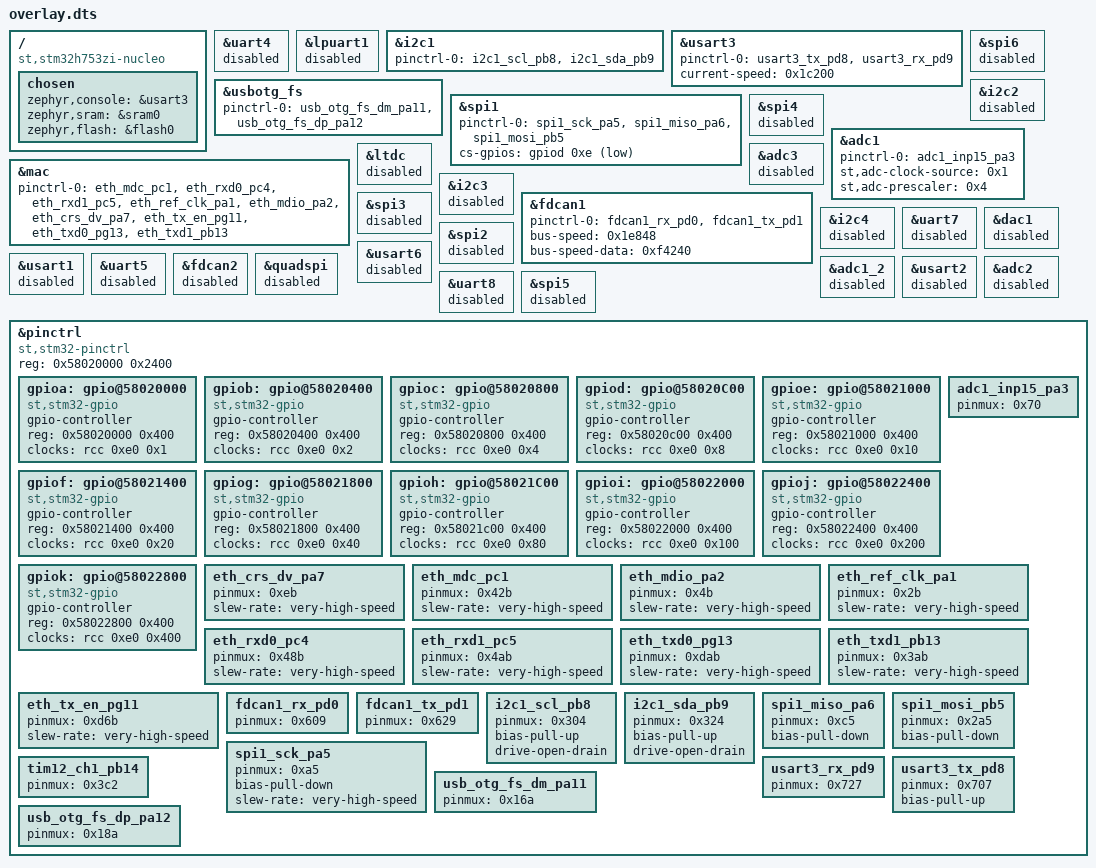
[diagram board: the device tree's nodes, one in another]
/ {
	compatible = "st,stm32h753zi-nucleo";
	chosen {
		zephyr,console = &usart3;
		zephyr,sram = &sram0;
		zephyr,flash = &flash0;
	};
};
&uart4{
	status = "disabled";
};
&lpuart1{
	status = "disabled";
};
&i2c1{
	status = "okay";
	pinctrl-0 = < &i2c1_scl_pb8 &i2c1_sda_pb9 >;
	pinctrl-names = "default";
};
&usart3{
	status = "okay";
	pinctrl-0 = < &usart3_tx_pd8 &usart3_rx_pd9 >;
	pinctrl-names = "default";
	current-speed = < 0x1c200 >;
};
&usbotg_fs{
	status = "okay";
	pinctrl-0 = < &usb_otg_fs_dm_pa11 &usb_otg_fs_dp_pa12 >;
	pinctrl-names = "default";
};
&spi6{
	status = "disabled";
};
&spi1{
	status = "okay";
	pinctrl-0 = < &spi1_sck_pa5 &spi1_miso_pa6 &spi1_mosi_pb5 >;
	pinctrl-names = "default";
	cs-gpios = < &gpiod 0xe 0x11 >;
};
&i2c2{
	status = "disabled";
};
&spi4{
	status = "disabled";
};
&adc1{
	status = "okay";
	pinctrl-0 = < &adc1_inp15_pa3 >;
	pinctrl-names = "default";
	st,adc-clock-source = < 0x1 >;
	st,adc-prescaler = < 0x4 >;
};
&mac{
	status = "okay";
	pinctrl-0 = < &eth_mdc_pc1 &eth_rxd0_pc4 &eth_rxd1_pc5 &eth_ref_clk_pa1 &eth_mdio_pa2 &eth_crs_dv_pa7 &eth_tx_en_pg11 &eth_txd0_pg13 &eth_txd1_pb13 >;
	pinctrl-names = "default";
};
&ltdc{
	status = "disabled";
};
&adc3{
	status = "disabled";
};
&i2c3{
	status = "disabled";
};
&fdcan1{
	status = "okay";
	pinctrl-0 = < &fdcan1_rx_pd0 &fdcan1_tx_pd1 >;
	pinctrl-names = "default";
	bus-speed = < 0x1e848 >;
	bus-speed-data = < 0xf4240 >;
};
&spi3{
	status = "disabled";
};
&i2c4{
	status = "disabled";
};
&uart7{
	status = "disabled";
};
&dac1{
	status = "disabled";
};
&spi2{
	status = "disabled";
};
&usart6{
	status = "disabled";
};
&usart1{
	status = "disabled";
};
&uart5{
	status = "disabled";
};
&fdcan2{
	status = "disabled";
};
&quadspi{
	status = "disabled";
};
&adc1_2{
	status = "disabled";
};
&usart2{
	status = "disabled";
};
&adc2{
	status = "disabled";
};
&uart8{
	status = "disabled";
};
&spi5{
	status = "disabled";
};
&pinctrl{
	compatible = "st,stm32-pinctrl";
	#address-cells = < 0x1 >;
	#size-cells = < 0x1 >;
	reg = < 0x58020000 0x2400 >;
	gpioa: gpio@58020000 {
		compatible = "st,stm32-gpio";
		gpio-controller;
		#gpio-cells = < 0x2 >;
		reg = < 0x58020000 0x400 >;
		clocks = < &rcc 0xe0 0x1 >;
	};
	gpiob: gpio@58020400 {
		compatible = "st,stm32-gpio";
		gpio-controller;
		#gpio-cells = < 0x2 >;
		reg = < 0x58020400 0x400 >;
		clocks = < &rcc 0xe0 0x2 >;
	};
	gpioc: gpio@58020800 {
		compatible = "st,stm32-gpio";
		gpio-controller;
		#gpio-cells = < 0x2 >;
		reg = < 0x58020800 0x400 >;
		clocks = < &rcc 0xe0 0x4 >;
	};
	gpiod: gpio@58020C00 {
		compatible = "st,stm32-gpio";
		gpio-controller;
		#gpio-cells = < 0x2 >;
		reg = < 0x58020c00 0x400 >;
		clocks = < &rcc 0xe0 0x8 >;
	};
	gpioe: gpio@58021000 {
		compatible = "st,stm32-gpio";
		gpio-controller;
		#gpio-cells = < 0x2 >;
		reg = < 0x58021000 0x400 >;
		clocks = < &rcc 0xe0 0x10 >;
	};
	gpiof: gpio@58021400 {
		compatible = "st,stm32-gpio";
		gpio-controller;
		#gpio-cells = < 0x2 >;
		reg = < 0x58021400 0x400 >;
		clocks = < &rcc 0xe0 0x20 >;
	};
	gpiog: gpio@58021800 {
		compatible = "st,stm32-gpio";
		gpio-controller;
		#gpio-cells = < 0x2 >;
		reg = < 0x58021800 0x400 >;
		clocks = < &rcc 0xe0 0x40 >;
	};
	gpioh: gpio@58021C00 {
		compatible = "st,stm32-gpio";
		gpio-controller;
		#gpio-cells = < 0x2 >;
		reg = < 0x58021c00 0x400 >;
		clocks = < &rcc 0xe0 0x80 >;
	};
	gpioi: gpio@58022000 {
		compatible = "st,stm32-gpio";
		gpio-controller;
		#gpio-cells = < 0x2 >;
		reg = < 0x58022000 0x400 >;
		clocks = < &rcc 0xe0 0x100 >;
	};
	gpioj: gpio@58022400 {
		compatible = "st,stm32-gpio";
		gpio-controller;
		#gpio-cells = < 0x2 >;
		reg = < 0x58022400 0x400 >;
		clocks = < &rcc 0xe0 0x200 >;
	};
	gpiok: gpio@58022800 {
		compatible = "st,stm32-gpio";
		gpio-controller;
		#gpio-cells = < 0x2 >;
		reg = < 0x58022800 0x400 >;
		clocks = < &rcc 0xe0 0x400 >;
	};
	adc1_inp15_pa3: adc1_inp15_pa3 {
		pinmux = < 0x70 >;
	};
	eth_crs_dv_pa7: eth_crs_dv_pa7 {
		pinmux = < 0xeb >;
		slew-rate = "very-high-speed";
	};
	eth_mdc_pc1: eth_mdc_pc1 {
		pinmux = < 0x42b >;
		slew-rate = "very-high-speed";
	};
	eth_mdio_pa2: eth_mdio_pa2 {
		pinmux = < 0x4b >;
		slew-rate = "very-high-speed";
	};
	eth_ref_clk_pa1: eth_ref_clk_pa1 {
		pinmux = < 0x2b >;
		slew-rate = "very-high-speed";
	};
	eth_rxd0_pc4: eth_rxd0_pc4 {
		pinmux = < 0x48b >;
		slew-rate = "very-high-speed";
	};
	eth_rxd1_pc5: eth_rxd1_pc5 {
		pinmux = < 0x4ab >;
		slew-rate = "very-high-speed";
	};
	eth_txd0_pg13: eth_txd0_pg13 {
		pinmux = < 0xdab >;
		slew-rate = "very-high-speed";
	};
	eth_txd1_pb13: eth_txd1_pb13 {
		pinmux = < 0x3ab >;
		slew-rate = "very-high-speed";
	};
	eth_tx_en_pg11: eth_tx_en_pg11 {
		pinmux = < 0xd6b >;
		slew-rate = "very-high-speed";
	};
	fdcan1_rx_pd0: fdcan1_rx_pd0 {
		pinmux = < 0x609 >;
	};
	fdcan1_tx_pd1: fdcan1_tx_pd1 {
		pinmux = < 0x629 >;
	};
	i2c1_scl_pb8: i2c1_scl_pb8 {
		pinmux = < 0x304 >;
		bias-pull-up;
		drive-open-drain;
	};
	i2c1_sda_pb9: i2c1_sda_pb9 {
		pinmux = < 0x324 >;
		bias-pull-up;
		drive-open-drain;
	};
	spi1_miso_pa6: spi1_miso_pa6 {
		pinmux = < 0xc5 >;
		bias-pull-down;
	};
	spi1_mosi_pb5: spi1_mosi_pb5 {
		pinmux = < 0x2a5 >;
		bias-pull-down;
	};
	spi1_sck_pa5: spi1_sck_pa5 {
		pinmux = < 0xa5 >;
		bias-pull-down;
		slew-rate = "very-high-speed";
	};
	tim12_ch1_pb14: tim12_ch1_pb14 {
		pinmux = < 0x3c2 >;
	};
	usart3_rx_pd9: usart3_rx_pd9 {
		pinmux = < 0x727 >;
	};
	usart3_tx_pd8: usart3_tx_pd8 {
		pinmux = < 0x707 >;
		bias-pull-up;
	};
	usb_otg_fs_dm_pa11: usb_otg_fs_dm_pa11 {
		pinmux = < 0x16a >;
	};
	usb_otg_fs_dp_pa12: usb_otg_fs_dp_pa12 {
		pinmux = < 0x18a >;
	};
};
